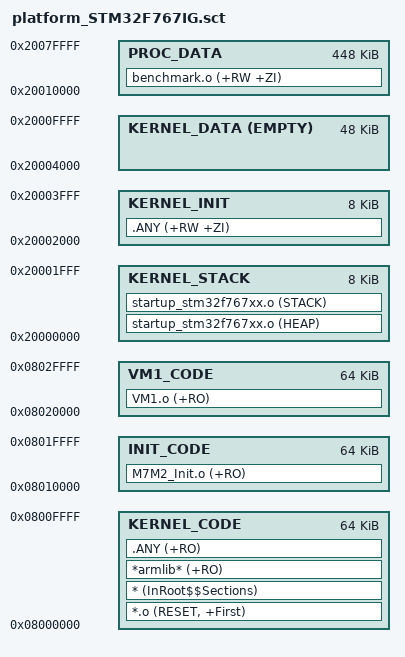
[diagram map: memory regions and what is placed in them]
;******************************************************************************
;Filename    : platform_STM32F767IG.sct
;Author      : pry
;Date        : 24/06/2017
;Licence     : LGPL v3+; see COPYING for details.
;Description : The scatter file for Cortex-M7 layout. This file is intended 
;              to be used with STM32F767IGT6.
;              ROM: 0x08000000 0x00100000
;              RAM: 0x20000000 0x00080000
;              System ROM layout:
;              |0x08000000            0x0800FFFF|0x08010000         0x080FFFFF|
;              |<-           Kernel           ->|<-           User          ->|
;              System RAM layout:
;              |0x20000000            0x20001FFF|0x20002000         0x20003FFF|
;              |<-        Kernel Stack        ->|<-        Kernel Data      ->|
;              |0x20004000            0x2000FFFF|0x20010000         0x2007FFFF|
;              |<-       Kernel Objects       ->|<-           User          ->|
;******************************************************************************

; Begin Segment:KERNEL ********************************************************
; Description : The kernel segment, this is where the kernel of the operating
;               system is located at. This segment also contains the .bss(ZI)
;               for processes.
; *****************************************************************************
KERNEL 0x08000000 0x00010000
{   
    ; Kernel code segment - 64kB
    KERNEL_CODE 0x08000000 0x00010000
    {   ; The reset vectors
        *.o                            (RESET, +First)
        ; The lib code copying code
        *                              (InRoot$$Sections)
        ; The ARM C library code - all of them is here
        *armlib*                       (+RO)
        ; The kernel code section
        .ANY                           (+RO)
    }
    
    ; Kernel stack segment - 8kB
    KERNEL_STACK 0x20000000 0x00002000
    {
        startup_stm32f767xx.o          (HEAP)
        startup_stm32f767xx.o          (STACK)
    }
    
    ; Initial kernel data segment - 8kB 
    KERNEL_INIT 0x20002000 0x00002000
    {
        .ANY                           (+RW +ZI)
    }
    
    ; Dynamically managed kernel data segment - 48kB
    KERNEL_DATA 0x20004000 EMPTY 0x0000C000
    {
        
    }
    
    ; The data section of the processes - The rest of the memory
    PROC_DATA 0x20010000 0x00070000
    {
        benchmark.o                    (+RW +ZI)
    }
}
; End Segment:KERNEL **********************************************************

; Begin Segment:INIT **********************************************************
; Description : The .text segment of process INIT. Init is the first process
;               in the system, and should act as a memory manager itself.
;               The .RODATA size if this process is 0x00010000.
; *****************************************************************************
INIT 0x08010000 0x00010000
{
    ; Init process code segment - 64kB
    INIT_CODE 0x08010000 0x00010000
    {
        M7M2_Init.o                    (+RO)
    }
}
; End Segment:INIT ************************************************************

; Begin Segment:VM1 ***********************************************************
; Description : The .text segment of the first virtual machine.
; *****************************************************************************
VM1 0x08020000 0x00010000
{
    ; Init process code segment - 64kB
    VM1_CODE 0x08020000 0x00010000
    {
        VM1.o                    (+RO)
    }
}
; End Segment:PROCESS1 ********************************************************

; End Of File *****************************************************************

; Copyright (C) Evo-Devo Instrum. All rights reserved *************************

